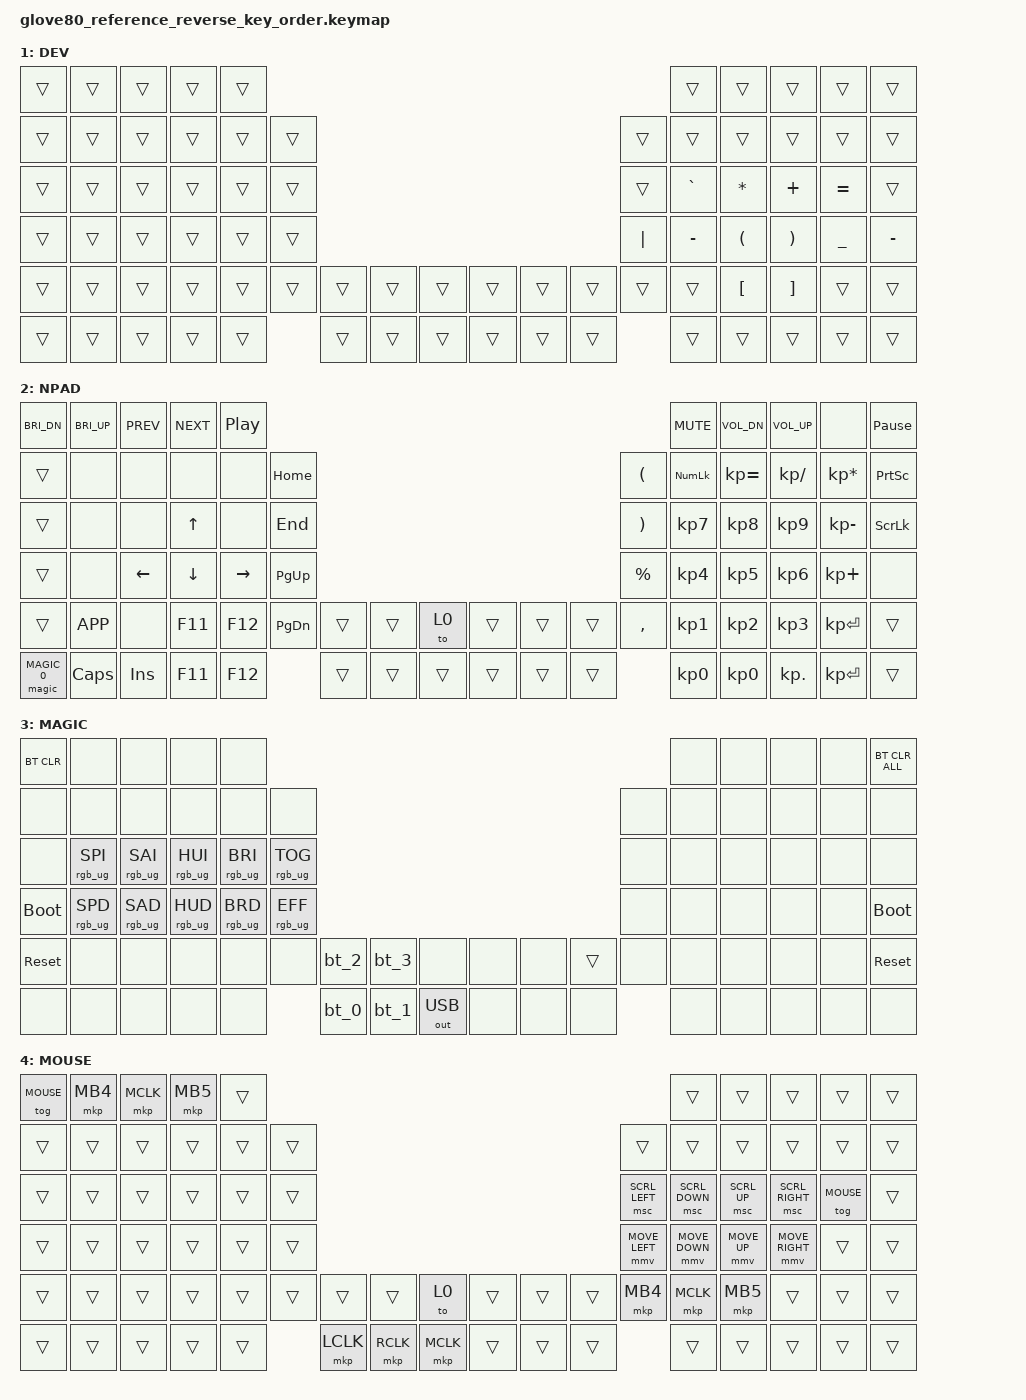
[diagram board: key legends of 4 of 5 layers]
/ {
    keymap {
        compatible = "zmk,keymap";
        BASE {
            bindings = <
    &kp F1          &kp F2           &kp F3           &kp F4           &kp F5                                                                                                                               &kp F6          &kp F7        &kp F8           &kp F9           &kp F10
    &kp EQUAL       &kp N1           &kp N2           &kp N3           &kp N4           &kp N5                                                                                              &kp N6          &kp N7          &kp N8        &kp N9           &kp N0           &kp MINUS
    &kp TAB         &kp Q            &ltl MOUSE W     &kp E            &kp R            &kp T                                                                                               &kp Y           &kp U           &kp I         &kp O            &kp P            &kp BSLH
    &kp ESC         &kp A            &hml LGUI S      &hml LALT D      &hml LCTRL F     &ltl NPAD G                                                                                         &ltr NPAD H     &hmr RCTRL J    &hmr RALT K   &hmr RGUI L      &kp SEMI         &kp SQT
    &kp GRAVE       &kp Z            &kp X            &kp C            &kp V            &kp B            &kp DEL    &kp LGUI   &kp ESC        &kp LCTRL  &kp RGUI                &kp RET    &kp N           &kp M           &kp COMMA     &kp DOT          &kp FSLH         &kp PG_UP
    &magic MAGIC 0  &lt 2 HOME       &kp END          &kp LEFT         &kp RIGHT                         &kp BSPC   &kp LSHFT  &ltl DEV LALT  &kp RET    &hmrt RSHFT &caps_word  &kp SPACE                  &kp UP          &kp DOWN      &kp LBKT         &kp RBKT         &kp PG_DN
            >;
        };
        DEV {
            bindings = <
    &trans          &trans           &trans           &trans           &trans                                                                                                                               &trans          &trans        &trans           &trans           &trans
    &trans          &trans           &trans           &trans           &trans           &trans                                                                                              &trans          &trans          &trans        &trans           &trans           &trans
    &trans          &trans           &trans           &trans           &trans           &trans                                                                                              &trans          &kp GRAVE       &kp STAR      &kp PLUS         &kp EQUAL        &trans
    &trans          &trans           &trans           &trans           &trans           &trans                                                                                              &kp PIPE        &kp MINUS       &kp LPAR      &kp RPAR         &kp UNDERSCORE   &kp MINUS
    &trans          &trans           &trans           &trans           &trans           &trans           &trans     &trans     &trans         &trans     &trans                  &trans     &trans          &trans          &kp LBKT      &kp RBKT         &trans           &trans
    &trans          &trans           &trans           &trans           &trans                            &trans     &trans     &trans         &trans     &trans                  &trans                     &trans          &trans        &trans           &trans           &trans
            >;
        };
        NPAD {
            bindings = <
    &kp C_BRI_DN    &kp C_BRI_UP     &kp C_PREV       &kp C_NEXT       &kp C_PP                                                                                                                             &kp C_MUTE      &kp C_VOL_DN  &kp C_VOL_UP     &none            &kp PAUSE_BREAK
    &trans          &none            &none            &none            &none            &kp HOME                                                                                            &kp LPAR        &kp KP_NUM      &kp KP_EQUAL  &kp KP_SLASH     &kp KP_MULTIPLY  &kp PRINTSCREEN
    &trans          &none            &none            &kp UP_ARROW     &none            &kp END                                                                                             &kp RPAR        &kp KP_N7       &kp KP_N8     &kp KP_N9        &kp KP_MINUS     &kp SCROLLLOCK
    &trans          &none            &kp LEFT_ARROW   &kp DOWN_ARROW   &kp RIGHT_ARROW  &kp PG_UP                                                                                           &kp PERCENT     &kp KP_N4       &kp KP_N5     &kp KP_N6        &kp KP_PLUS      &none
    &trans          &kp K_APP        &none            &kp F11          &kp F12          &kp PG_DN        &trans     &trans     &to 0          &trans     &trans                  &trans     &kp COMMA       &kp KP_N1       &kp KP_N2     &kp KP_N3        &kp KP_ENTER     &trans
    &magic MAGIC 0  &kp CAPS         &kp INS          &kp F11          &kp F12                           &trans     &trans     &trans         &trans     &trans                  &trans                     &kp KP_N0       &kp KP_N0     &kp KP_DOT       &kp KP_ENTER     &trans
            >;
        };
        MAGIC {
            bindings = <
    &bt BT_CLR      &none            &none            &none            &none                                                                                                                                &none           &none         &none            &none            &bt BT_CLR_ALL
    &none           &none            &none            &none            &none            &none                                                                                               &none           &none           &none         &none            &none            &none
    &none           &rgb_ug RGB_SPI  &rgb_ug RGB_SAI  &rgb_ug RGB_HUI  &rgb_ug RGB_BRI  &rgb_ug RGB_TOG                                                                                     &none           &none           &none         &none            &none            &none
    &bootloader     &rgb_ug RGB_SPD  &rgb_ug RGB_SAD  &rgb_ug RGB_HUD  &rgb_ug RGB_BRD  &rgb_ug RGB_EFF                                                                                     &none           &none           &none         &none            &none            &bootloader
    &sys_reset      &none            &none            &none            &none            &none            &bt_2      &bt_3      &none          &none      &none                   &trans     &none           &none           &none         &none            &none            &sys_reset
    &none           &none            &none            &none            &none                             &bt_0      &bt_1      &out OUT_USB   &none      &none                   &none                      &none           &none         &none            &none            &none
            >;
        };
        MOUSE {
            bindings = <
    &tog MOUSE      &mkp MB4         &mkp MCLK        &mkp MB5         &trans                                                                                                                               &trans          &trans        &trans           &trans           &trans
    &trans          &trans           &trans           &trans           &trans           &trans                                                                                              &trans          &trans          &trans        &trans           &trans           &trans
    &trans          &trans           &trans           &trans           &trans           &trans                                                                                              &msc SCRL_LEFT  &msc SCRL_DOWN  &msc SCRL_UP  &msc SCRL_RIGHT  &tog MOUSE       &trans
    &trans          &trans           &trans           &trans           &trans           &trans                                                                                              &mmv MOVE_LEFT  &mmv MOVE_DOWN  &mmv MOVE_UP  &mmv MOVE_RIGHT  &trans           &trans
    &trans          &trans           &trans           &trans           &trans           &trans           &trans     &trans     &to 0          &trans     &trans                  &trans     &mkp MB4        &mkp MCLK       &mkp MB5      &trans           &trans           &trans
    &trans          &trans           &trans           &trans           &trans                            &mkp LCLK  &mkp RCLK  &mkp MCLK      &trans     &trans                  &trans                     &trans          &trans        &trans           &trans           &trans
            >;
        };
    };
};
